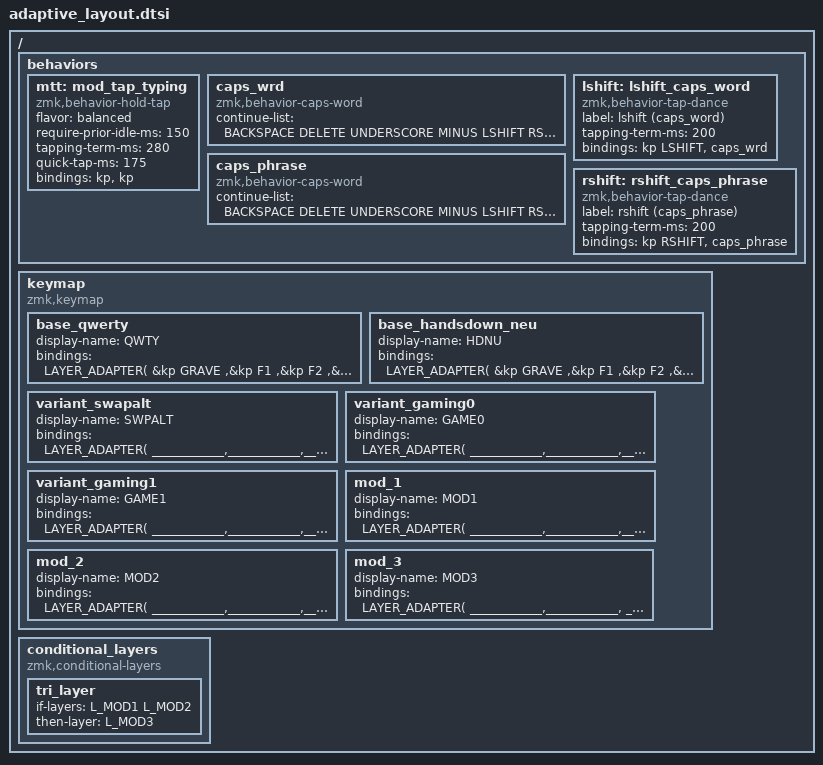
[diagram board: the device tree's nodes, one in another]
/****************************************************************************************************************/
/*                                                  ADAPTIVE LAYOUT                                             */
/****************************************************************************************************************/
// 
//    ┌─────┬─────┬─────┬─────┬─────┬─────┬─────┐                  ┌─────┬─────┬─────┬─────┬─────┬─────┬─────┐
//    |  -  |  -  |  -  |  -  |  -  |  -  |  -  |                  |  -  |  -  |  -  |  -  |  -  |  -  |  -  |
//    └─────┴─────┴─────┴─────┴─────┴─────┼─────┤                  ┼─────┤─────┴─────┴─────┴─────┴─────┴─────┘
// ┌─────┬─────┬─────┬─────┬─────┬─────┐  |  -  |                  |  -  |  ┌─────┬─────┬─────┬─────┬─────┬─────┐
// | ESC |  1  |  2  |  3  |  4  |  5  |  ├─────┤                  ├─────┤  |  6  |  7  |  8  |  9  |  0  | BCK |
// ├─────┼─────┼─────┼─────┼─────┼─────┤  |  -  |                  |  -  |  ├─────┼─────┼─────┼─────┼─────┼─────┤
// | TAB |  Q  |  W  |  E  |  R  |  Y  |  ├─────┤                  ├─────┤  |  Y  |  U  |  I  |  O  |  P  | CTL |
// ├─────┼─────┼─────┼─────┼─────┼─────┤  |  -  |                  |  -  |  ├─────┼─────┼─────┼─────┼─────┼─────┤
// | CTL |  A  |  S  |  D  |  F  |  G  |  └─────┘                  └─────┘  |  H  |  J  |  K  |  L  |  ;  |  '  |
// ├─────┼─────┼─────┼─────┼─────┼─────┤                                    ├─────┼─────┼─────┼─────┼─────┼─────┤
// | SHF |  Z  |  X  |  C  |  V  |  B  |  ┌─────┬─────┐      ┌─────┬─────┐  |  N  |  M  |  ,  |  .  |  /  | SHF |
// └─────┴─────┴─────┴─────┴─────┴─────┘  |  -  |  -  |      |  -  |  -  |  └─────┴─────┴─────┴─────┴─────┴─────┘
// ┌─────┬─────┬─────┐  ┌─────┬─────┬─────┼─────┼─────┤      ├─────┼─────┼─────┬─────┬─────┐  ┌─────┬─────┬─────┐
// |  -  |  -  |  -  |  | ALT |  ∞  | MOD |  -  |  -  |      |  -  | ENT | MOD | ALT |  ∞  |  |  -  |  -  |  -  |
// └─────┴─────┴─────┘  └─────┴─────┴─────┴─────┴─────┘      └─────┴─────┴─────┴─────┴─────┘  └─────┴─────┴─────┘

#include <behaviors.dtsi>
#include <dt-bindings/zmk/keys.h>
#include <dt-bindings/zmk/bt.h>

// KEY ALIAS
#define ____________  &trans

// LAYER REFERENCES
#define L_BQWTY   0 // BASE qwerty
#define L_BHDNU   1 // BASE handsdown neu

#define L_VALTSWP 2 // VARIANT swap LALT
#define L_VGAME0  3 // VARIANT gaming (no quirks)
#define L_VGAME1  4 // VARIANT gaming (no quirks + lhand cols shifted right)

#define L_MOD1 5 // MOD layer 1
#define L_MOD2 6 // MOD layer 2
#define L_MOD3 7 // MOD layer 3

/ {
        behaviors {
                // Mod tap on key used for typing
                mtt: mod_tap_typing {
                        compatible = "zmk,behavior-hold-tap";
                        #binding-cells = <2>;
                        flavor = "balanced";
                        require-prior-idle-ms = <150>;
                        tapping-term-ms = <280>;
                        quick-tap-ms = <175>;
                        bindings = <&kp>, <&kp>;
                };
                // CAPS WORD behaviors
                caps_wrd: caps_wrd {
                        compatible = "zmk,behavior-caps-word";
                        #binding-cells = <0>;
                        continue-list = <BACKSPACE DELETE UNDERSCORE MINUS LSHIFT RSHIFT>;
                };
                caps_phrase: caps_phrase {
                        compatible = "zmk,behavior-caps-word";
                        #binding-cells = <0>;
                        continue-list = <BACKSPACE DELETE UNDERSCORE MINUS LSHIFT RSHIFT SPACE>;
                };
                lshift: lshift_caps_word {
                        compatible = "zmk,behavior-tap-dance";
                        label = "lshift (caps_word)";
                        #binding-cells = <0>;
                        tapping-term-ms = <200>;
                        bindings = <&kp LSHIFT>, <&caps_wrd>;
                };
                rshift: rshift_caps_phrase {
                        compatible = "zmk,behavior-tap-dance";
                        label = "rshift (caps_phrase)";
                        #binding-cells = <0>;
                        tapping-term-ms = <200>;
                        bindings = <&kp RSHIFT>, <&caps_phrase>;
                };
                // LAYERS
                // TODO: I want a "toc" behavior (cycle) that toggles between all provided layers
        };

        keymap {
                compatible = "zmk,keymap";

                base_qwerty {
                        display-name = "QWTY";
                        bindings = <LAYER_ADAPTER(
  &kp GRAVE   ,&kp F1      ,&kp F2      ,&kp F3      ,&kp F4      ,&kp F5      ,&kp F6      ,                          &kp F7      ,&kp F8      ,&kp F9      ,&kp F10     ,&kp F11     ,&kp F12     ,&trans      ,
                                                                                ____________,                          ____________,                                                                  
  &kp ESC     ,&kp N1      ,&kp N2      ,&kp N3      ,&kp N4      ,&kp N5      ,____________,                          ____________,&kp N6      ,&kp N7      ,&kp N8      ,&kp N9      ,&kp N0      ,&kp BSPC    ,
  &kp TAB     ,&kp Q       ,&kp W       ,&kp E       ,&kp R       ,&kp T       ,____________,                          ____________,&kp Y       ,&kp U       ,&kp I       ,&kp O       ,&kp P       ,&kp RCTRL   ,
  &kp LCTRL   ,&kp A       ,&kp S       ,&kp D       ,&kp F       ,&kp G       ,                                                    &kp H       ,&kp J       ,&kp K       ,&kp L       ,&kp SEMI    ,&mtt RCTRL SQT,
  &lshift     ,&kp Z       ,&kp X       ,&kp C       ,&kp V       ,&kp B       ,                                                    &kp N       ,&kp M       ,&kp COMMA   ,&kp DOT     ,&kp FSLH    ,&rshift,
                                                                                &bt BT_NXT  ,&trans      ,&trans      ,&kp DEL     ,
  ____________,____________,____________,&kp LALT    ,&kp LMETA   ,&mo L_MOD1  ,&kp SPACE   ,____________,____________,&mt RALT RET,&mo L_MOD2  ,&kp RMETA   ,&kp RALT    ,____________,____________,____________
                        )>;
                };
                base_handsdown_neu {
                        display-name = "HDNU";
                        bindings = <LAYER_ADAPTER(
  &kp GRAVE   ,&kp F1      ,&kp F2      ,&kp F3      ,&kp F4      ,&kp F5      ,&kp F6      ,                          &kp F7      ,&kp F8      ,&kp F9      ,&kp F10     ,&kp F11     ,&kp F12     ,&trans      ,
                                                                                ____________,                          ____________,                                                                  
  &kp ESC     ,&kp N1      ,&kp N2      ,&kp N3      ,&kp N4      ,&kp N5      ,____________,                          ____________,&kp N6      ,&kp N7      ,&kp N8      ,&kp N9      ,&kp N0      ,&kp BSPC    ,
  &kp TAB     ,&kp W       ,&kp F       ,&kp M       ,&kp P       ,&kp V       ,____________,                          ____________,&kp FSLH    ,&kp DOT     ,&kp Q       ,&kp SQT     ,&kp Z       ,&kp RCTRL   ,
  &kp LCTRL   ,&kp R       ,&kp S       ,&kp N       ,&kp T       ,&kp B       ,                                                    &kp COMMA   ,&kp A       ,&kp E       ,&kp I       ,&kp H       ,&mtt RCTRL SEMI,
  &lshift     ,&kp X       ,&kp C       ,&kp L       ,&kp D       ,&kp G       ,                                                    &kp J       ,&kp U       ,&kp O       ,&kp Y       ,&kp K       ,&rshift     ,
                                                                                &bt BT_NXT  ,&trans      ,&trans      ,&kp DEL     ,
  ____________,____________,____________,&kp LALT    ,&kp LMETA   ,&mo L_MOD1  ,&kp SPACE   ,____________,____________,&mt RALT RET,&mo L_MOD2  ,&kp RMETA   ,&kp RALT    ,____________,____________,____________
                        )>;
                };
                variant_swapalt {
                        display-name = "SWPALT";
                        bindings = <LAYER_ADAPTER(
  ____________,____________,____________,____________,____________,____________,____________,                          ____________,____________,____________,____________,____________,____________,____________,
                                                                                ____________,                          ____________,                                                                              
  ____________,____________,____________,____________,____________,____________,____________,                          ____________,____________,____________,____________,____________,____________,____________,
  ____________,____________,____________,____________,____________,____________,____________,                          ____________,____________,____________,____________,____________,____________,____________,
  ____________,____________,____________,____________,____________,____________,                                                    ____________,____________,____________,____________,____________,____________,
  ____________,____________,____________,____________,____________,____________,                                                    ____________,____________,____________,____________,____________,____________,
                                                                                ____________,____________,____________,____________,                                                                              
  ____________,____________,____________,&kp LMETA,   &kp LALT,    ____________,____________,____________,____________,____________,____________,&kp RALT    ,&kp RMETA   ,____________,____________,____________
                        )>;
                };
                variant_gaming0 {
                        display-name = "GAME0";
                        bindings = <LAYER_ADAPTER(
  ____________,____________,____________,____________,____________,____________,____________,                          ____________,____________,____________,____________,____________,____________,____________,
                                                                                ____________,                          ____________,                                                                              
  &kp ESC     ,&kp N1      ,&kp N2      ,&kp N3      ,&kp N4      ,&kp N5      ,____________,                          ____________,&kp N6      ,&kp N7      ,&kp N8      ,&kp N9      ,&kp N0      ,&kp BSPC    ,
  &kp TAB     ,&kp Q       ,&kp W       ,&kp E       ,&kp R       ,&kp T       ,____________,                          ____________,&kp Y       ,&kp U       ,&kp I       ,&kp O       ,&kp P       ,&kp RCTRL   ,
  &kp LCTRL   ,&kp A       ,&kp S       ,&kp D       ,&kp F       ,&kp G       ,                                                    &kp H       ,&kp J       ,&kp K       ,&kp L       ,&kp SEMI    ,&kp SQT     ,
  &kp LSHIFT  ,&kp Z       ,&kp X       ,&kp C       ,&kp V       ,&kp B       ,                                                    &kp N       ,&kp M       ,&kp COMMA   ,&kp DOT     ,&kp FSLH    ,&kp RSHIFT  ,
                                                                                ____________,____________,____________,____________,                                                                              
  ____________,____________,____________,____________,____________,____________,____________,____________,____________,____________,____________,____________,____________,____________,____________,____________
                        )>;
                };
                variant_gaming1 {
                        display-name = "GAME1";
                        bindings = <LAYER_ADAPTER(
  ____________,____________,____________,____________,____________,____________,____________,                          ____________,____________,____________,____________,____________,____________,____________,
                                                                                ____________,                          ____________,                                                                              
  &kp ESC     ,&kp N5      ,&kp N1      ,&kp N2      ,&kp N3      ,&kp N4      ,____________,                          ____________,&kp N6      ,&kp N7      ,&kp N8      ,&kp N9      ,&kp N0      ,&kp BSPC    ,
  &kp TAB     ,&kp T       ,&kp Q       ,&kp W       ,&kp E       ,&kp R       ,____________,                          ____________,&kp Y       ,&kp U       ,&kp I       ,&kp O       ,&kp P       ,&kp RCTRL   ,
  &kp LCTRL   ,&kp G       ,&kp A       ,&kp S       ,&kp D       ,&kp F       ,                                                    &kp H       ,&kp J       ,&kp K       ,&kp L       ,&kp SEMI    ,&kp SQT     ,
  &kp LSHIFT  ,&kp B       ,&kp Z       ,&kp X       ,&kp C       ,&kp V       ,                                                    &kp N       ,&kp M       ,&kp COMMA   ,&kp DOT     ,&kp FSLH    ,&kp RSHIFT  ,
                                                                                ____________,____________,____________,____________,                                                                              
  ____________,____________,____________,____________,____________,____________,____________,____________,____________,____________,____________,____________,____________,____________,____________,____________
                        )>;
                };
                mod_1 {
                        display-name = "MOD1";
                        bindings = <LAYER_ADAPTER(
  ____________,____________,____________,____________,____________,____________,____________,                          ____________,____________,____________,____________,____________,____________,____________,
                                                                                ____________,                          ____________,                                                                              
  ____________,____________,____________,____________,____________,____________,____________,                          ____________,____________,____________,____________,____________,____________,____________,
  ____________,&kp EXCL    ,&kp AT      ,&kp HASH    ,&kp DLLR    ,&kp PRCNT   ,____________,                          ____________,&kp CARET   ,&kp AMPS    ,&kp ASTRK   ,&kp LPAR    ,&kp RPAR    ,____________,
  ____________,&kp ESC     ,&kp PIPE    ,&kp LBKT    ,&kp BSPC    ,&kp RBKT    ,                                                    &kp MINUS   ,&kp UNDER   ,&kp EQUAL   ,&kp PLUS    ,&kp BSLH    ,____________,
  ____________,&kp N1      ,&kp N2      ,&kp N3      ,&kp N4      ,&kp N5      ,                                                    &kp N6      ,&kp N7      ,&kp N8      ,&kp N9      ,&kp N0      ,____________,
                                                                                ____________,____________,____________,____________,                                                                              
  ____________,____________,____________,____________,&kp RALT,      ____________,____________,____________,____________,&kp HOME,  ____________,&kp END,     ____________,____________,____________,____________
                        )>;
                };

                mod_2 {
                        display-name = "MOD2";
                        bindings = <LAYER_ADAPTER(
  ____________,____________,____________,____________,____________,   ____________,____________,                             ____________,____________,____________,____________,____________,____________,____________,
                                                                                   ____________,                             ____________,                                                                              
  ____________,____________,____________,____________,____________,   ____________,____________,                             ____________,____________,____________,____________,____________,____________,____________,
  ____________,&kp EXCL    ,&kp AT      ,&kp HASH    ,&kp DLLR    ,   &kp PRCNT   ,____________,                             ____________,&kp CARET   ,&kp AMPS    ,&kp ASTRK   ,&kp LPAR    ,&kp RPAR    ,____________,
  ____________,&kp ESC     ,&kp GRAVE   ,&kp LBRC    ,&kp BSPC    ,   &kp RBRC    ,                                                       &kp LEFT    ,&kp DOWN    ,&kp UP      ,&kp RIGHT   ,&kp TILDE   ,____________,
  ____________,&kp N1      ,&kp N2      ,&kp N3      ,&kp N4      ,   &kp N5      ,                                                       &kp N6      ,&kp N7      ,&kp N8      ,&kp N9      ,&kp N0      ,____________,
                                                                                   ____________,   ____________,____________,____________,                                                                              
  ____________,____________,____________,____________,&mt LALT PG_UP, ____________,&mt RALT PG_DN, ____________,____________,____________,____________,____________,____________,____________,____________,____________
                        )>;
                };
                mod_3 {
                        display-name = "MOD3";
                        bindings = <LAYER_ADAPTER(
  ____________,____________,  ____________,   ____________,____________,____________,____________,                          ____________,____________,____________,____________,____________,____________,____________,
                                                                                     ____________,                          ____________,                                                                              
  ____________,____________,  ____________,   ____________,____________,____________,____________,                          ____________,____________,____________,____________,____________,____________,____________,
  ____________,&bt BT_PRV  ,  &bt BT_NXT  ,   ____________,____________,&bt BT_CLR  ,____________,                          ____________,____________,____________,____________,____________,____________,____________,
  ____________,&tog L_VGAME0, &tog L_VGAME1,  ____________,____________,____________,                                                     ____________,____________,____________,____________,____________,____________,
  ____________,&tog L_BHDNU,  &tog L_VALTSWP, ____________,____________,____________,                                                     ____________,____________,____________,____________,____________,____________,
                                                                                     ____________,____________,____________,____________,                                                                              
  ____________,____________,  ____________,   ____________,____________,____________,____________,____________,____________,____________,____________,____________,____________,____________,____________,____________
                        )>;
                };
        };

        conditional_layers {
                compatible = "zmk,conditional-layers";
                tri_layer {
                        if-layers = <L_MOD1 L_MOD2>;
                        then-layer = <L_MOD3>;
                };
        };
};
